VERSION ""

NS_ :

BS_:

BU_:

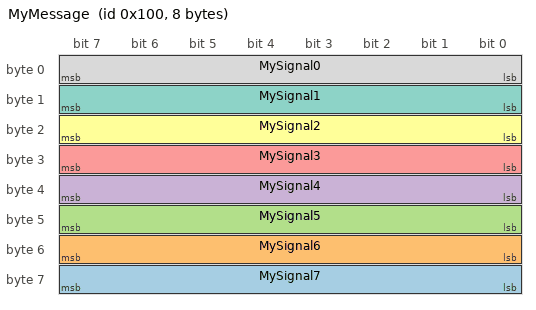
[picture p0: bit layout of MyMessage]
BO_ 256 MyMessage: 8 Vector__XXX
 SG_ MySignal7 : 56|8@1- (1,0) [0|0] "" Vector__XXX
 SG_ MySignal6 : 48|8@1- (1,0) [0|0] "" Vector__XXX
 SG_ MySignal5 : 40|8@1- (1,0) [0|0] "" Vector__XXX
 SG_ MySignal4 : 32|8@1- (1,0) [0|0] "" Vector__XXX
 SG_ MySignal3 : 24|8@1- (1,0) [0|0] "" Vector__XXX
 SG_ MySignal2 : 16|8@1- (1,0) [0|0] "" Vector__XXX
 SG_ MySignal1 : 8|8@1- (1,0) [0|0] "" Vector__XXX
 SG_ MySignal0 : 0|8@1- (1,0) [0|0] "" Vector__XXX

BA_DEF_ SG_  "GenSigSendType" ENUM  "Cyclic","OnWrite","OnWriteWithRepetition","OnChange","OnChangeWithRepetition","IfActive","IfActiveWithRepetition","NoSigSendType";
BA_DEF_ BO_  "GenMsgSendType" ENUM  "Cyclic","not_used","not_used","not_used","not_used","Cyclic","not_used","IfActive","NoMsgSendType";
BA_DEF_  "DBName" STRING ;
BA_DEF_  "BusType" STRING ;
BA_DEF_DEF_  "GenSigSendType" "Cyclic";
BA_DEF_DEF_  "GenMsgSendType" "NoMsgSendType";
BA_DEF_DEF_  "DBName" "";
BA_DEF_DEF_  "BusType" "CAN";
BA_ "DBName" "blftest";
